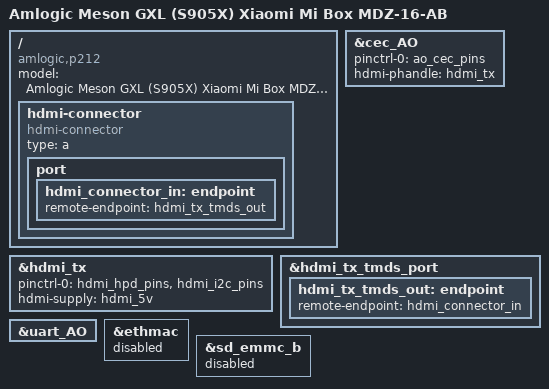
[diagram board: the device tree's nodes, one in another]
// SPDX-License-Identifier: (GPL-2.0+ OR MIT)
/*
 * Copyright (c) 2016 Endless Computers, Inc.
 * Author: Carlo Caione <carlo@endlessm.com>
 */

/dts-v1/;

#include "meson-gxl-s905x-p212.dtsi"

/ {
	compatible = "amlogic,p212", "amlogic,s905x", "amlogic,meson-gxl";
	model = "Amlogic Meson GXL (S905X) Xiaomi Mi Box MDZ-16-AB";

	hdmi-connector {
		compatible = "hdmi-connector";
		type = "a";

		port {
			hdmi_connector_in: endpoint {
				remote-endpoint = <&hdmi_tx_tmds_out>;
			};
		};
	};
};

&cec_AO {
	status = "okay";
	pinctrl-0 = <&ao_cec_pins>;
	pinctrl-names = "default";
	hdmi-phandle = <&hdmi_tx>;
};

&hdmi_tx {
	status = "okay";
	pinctrl-0 = <&hdmi_hpd_pins>, <&hdmi_i2c_pins>;
	pinctrl-names = "default";
	hdmi-supply = <&hdmi_5v>;
};

&hdmi_tx_tmds_port {
	hdmi_tx_tmds_out: endpoint {
		remote-endpoint = <&hdmi_connector_in>;
	};
};

/* This UART is brought out to the DB9 connector */
&uart_AO {
	status = "okay";
};

// the mi box does not have ethernet and the sd card connected
&ethmac {
	status = "disabled";
};

&sd_emmc_b {
	status = "disabled";
};
